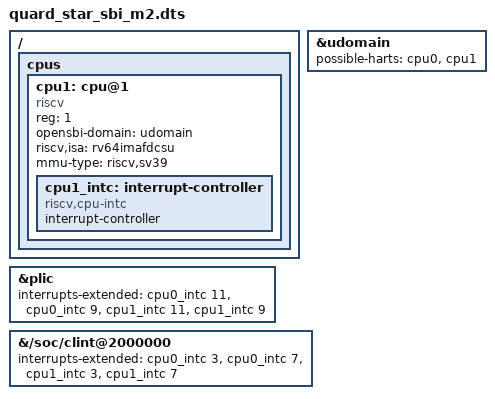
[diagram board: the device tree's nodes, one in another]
/include/ "quard_star_sbi.dts"

&udomain {
	possible-harts = <&cpu0 &cpu1>;
};

/ {
	cpus {
		cpu1: cpu@1 {
			device_type = "cpu";
			reg = <1>;
			status = "okay";
			compatible = "riscv";
			opensbi-domain = <&udomain>;
			riscv,isa = "rv64imafdcsu";
			mmu-type = "riscv,sv39";

			cpu1_intc: interrupt-controller {
				#interrupt-cells = <1>;
				interrupt-controller;
				compatible = "riscv,cpu-intc";
			};
		};
	};
};

&plic {
	interrupts-extended = <&cpu0_intc 11 &cpu0_intc 9
			       &cpu1_intc 11 &cpu1_intc 9>;
};

&{/soc/clint@2000000} {
	interrupts-extended = <&cpu0_intc 3 &cpu0_intc 7
			       &cpu1_intc 3 &cpu1_intc 7>;
};
